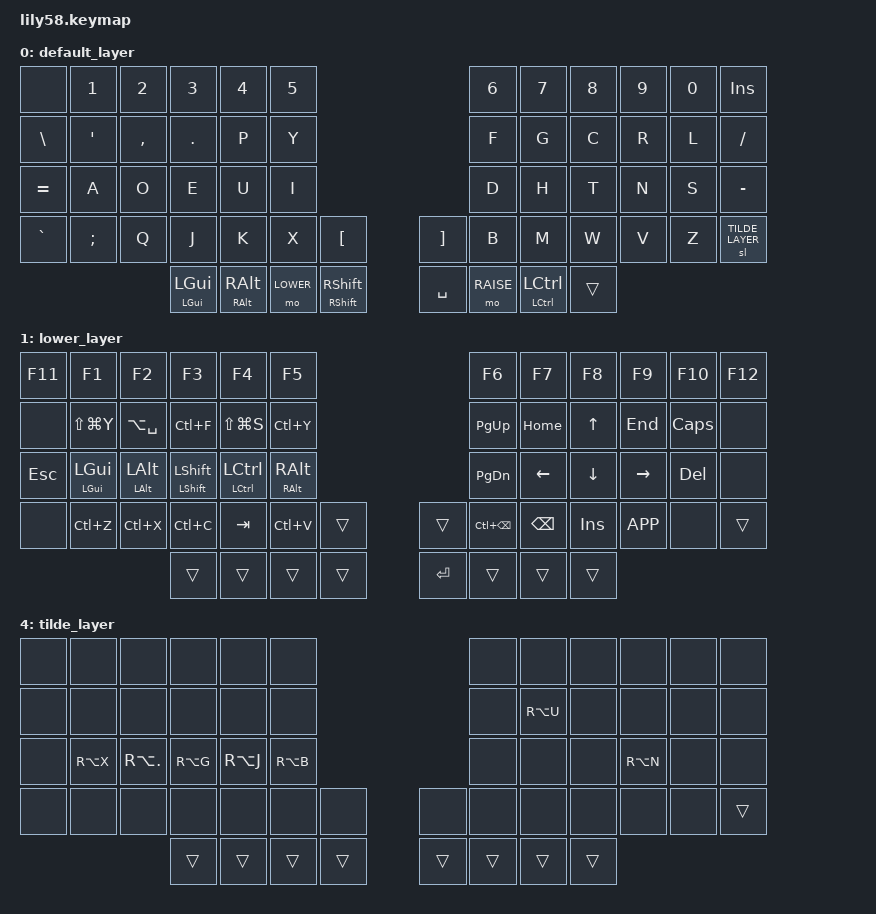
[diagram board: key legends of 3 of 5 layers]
/*
 * Copyright (c) 2020 The ZMK Contributors
 * SPDX-License-Identifier: MIT
 */

#include <behaviors.dtsi>
#include <dt-bindings/zmk/keys.h>
#include <dt-bindings/zmk/bt.h>
#include <dt-bindings/zmk/ext_power.h>


#define DEFAULT 0
#define LOWER   1
#define RAISE   2
#define ADJUST  3
#define TILDE_LAYER 4  

/ {
    behaviors {
         // COMPORTAMIENTOS BLUETOOTH-OPTIMIZADOS
    ht: hold_tap {
        #binding-cells = <2>;
        flavor = "tap-preferred";
        tapping-term-ms = <200>;
        quick-tap-ms = <120>;
        require-prior-idle-ms = <100>;  // REDUCIDO para Bluetooth
        bindings = <&kp>, <&kp>;
    };
    
    mt: mod_tap {
        #binding-cells = <2>;
        flavor = "hold-preferred";
        tapping-term-ms = <220>;
        bindings = <&kp>, <&kp>;
    };
           
    };

    kscan: kscan {
        compatible = "zmk,kscan-gpio-matrix";
    diode-direction = "col2row";
    debounce-press-ms = <15>;
    debounce-release-ms = <20>;
    wakeup-source;compatible = "zmk,kscan-gpio-matrix";
    diode-direction = "col2row";
    debounce-press-ms = <15>;
    debounce-release-ms = <20>;
    wakeup-source;
    };

    conditional_layers {
        compatible = "zmk,conditional-layers";
        tri_layer {
            if-layers = <LOWER RAISE>;
            then-layer = <ADJUST>;
        };
    };
};

/ {
    keymap {
        compatible = "zmk,keymap";

        // === Capa DEFAULT (Base) ===
        default_layer {
            bindings = <
                &none  &kp N1  &kp N2  &kp N3  &kp N4  &kp N5           &kp N6  &kp N7  &kp N8  &kp N9  &kp N0  &kp INS
                &kp BSLH        &kp SQT &kp COMMA &kp DOT &kp P   &kp Y           &kp F   &kp G   &kp C   &kp R   &kp L   &kp FSLH
                &kp EQUAL       &kp A   &kp O   &kp E   &kp U   &kp I             &kp D   &kp H   &kp T   &kp N   &kp S   &kp MINUS
                &kp GRAVE       &kp SEMI &kp Q  &kp J   &kp K   &kp X  &kp LBKT  &kp RBKT &kp B   &kp M   &kp W   &kp V   &kp Z   &sl TILDE_LAYER
                                            &mt LGUI LGUI &mt RALT RALT &mo LOWER &mt RSHFT RSHFT &kp SPACE &mo RAISE &mt LCTRL LCTRL &trans
            >;
        };

        // === Capa LOWER (Teclas de función y accesos directos) ===
        lower_layer {
            bindings = <
                &kp F11         &kp F1  &kp F2  &kp F3  &kp F4  &kp F5           &kp F6  &kp F7  &kp F8  &kp F9  &kp F10 &kp F12
                &none           &kp LS(LG(Y)) &kp LA(SPACE) &kp LC(F) &kp LS(LG(S)) &kp LC(Y) &kp PG_UP &kp HOME &kp UP &kp END &kp CAPS &none
                &kp ESC &mt LGUI LGUI &mt LALT LALT &mt LSHFT LSHFT &mt LCTRL LCTRL &mt RALT RALT     &kp PG_DN &kp LEFT &kp DOWN &kp RIGHT &kp DEL &none
                &none         &kp LC(Z) &kp LC(X) &kp LC(C) &kp TAB &kp LC(V)    &trans    &trans  &kp LC(BSPC) &kp BSPC &kp INS &kp K_APP &none &trans
                                                      &trans &trans &trans &trans &kp ENTER &trans &trans &trans
            >;
        };

        // === Capa RAISE (Números y controles básicos) ===
        raise_layer {
            bindings = <
                &none           &kp LG(N1) &kp LG(N2) &kp LG(N3) &kp LG(N4) &kp LG(N5)   &none    &none &none &none &none &none
                &none           &none      &none      &none      &none      &none        &none    &none &none &none &none &none
                &none           &none      &none      &none      &none      &none        &none    &none &none &none &none &none
                &none           &none      &none      &none      &none      &none  &none  &none    &none &none &none &none &trans
                                                      &trans &trans &trans &trans &trans &trans &trans &trans
            >;
        };

        // === Capa ADJUST (Controles multimedia y Bluetooth) ===
        adjust_layer {
            bindings = <
                &bt BT_CLR_ALL  &bt BT_SEL 0 &bt BT_SEL 1 &bt BT_SEL 2 &bt BT_SEL 3 &bt BT_SEL 4   &trans &trans &trans &trans &trans &trans
                &trans         &kp C_PREV   &kp C_PLAY   &kp C_NEXT   &kp C_VOL_DN &kp C_VOL_UP   &trans &trans &trans &trans &trans &trans
                &trans         &trans       &trans       &trans       &trans       &trans         &trans &trans &trans &trans &trans &trans
                &trans         &trans       &trans       &trans       &trans       &trans  &trans  &trans &trans &trans &trans &trans &trans
                                                      &trans &trans &trans &trans &trans &trans &trans &trans
            >;
        };

        // === Capa TILDE (Caracteres especiales) ===
        tilde_layer {
            bindings = <
                &none           &none &none &none &none &none                   &none &none &none &none &none &none
                &none           &none &none &none &none &none                   &none &kp RA(U) &none &none &none &none
                &none           &kp RA(X) &kp RA(DOT) &kp RA(G) &kp RA(J) &kp RA(B)  &none &none &none &kp RA(N) &none &none
                &none           &none &none &none &none &none  &none  &none      &none &none &none &none &none &trans
                                                      &trans &trans &trans &trans &trans &trans &trans &trans
            >;
        };
    };
};
